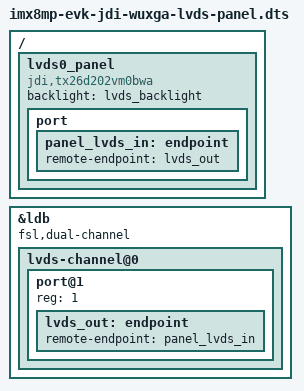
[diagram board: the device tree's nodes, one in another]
// SPDX-License-Identifier: GPL-2.0+
/*
 * Copyright 2020 NXP
 */

#include "imx8mp-evk.dts"

/ {
	lvds0_panel {
		compatible = "jdi,tx26d202vm0bwa";
		backlight = <&lvds_backlight>;

		port {
			panel_lvds_in: endpoint {
				remote-endpoint = <&lvds_out>;
			};
		};
	};
};

/delete-node/ &lvds_bridge;

&ldb {
	status = "okay";
	fsl,dual-channel;

	lvds-channel@0 {
		/delete-node/ port@1;

		port@1 {
			reg = <1>;

			lvds_out: endpoint {
				remote-endpoint = <&panel_lvds_in>;
			};
		};
	};
};
